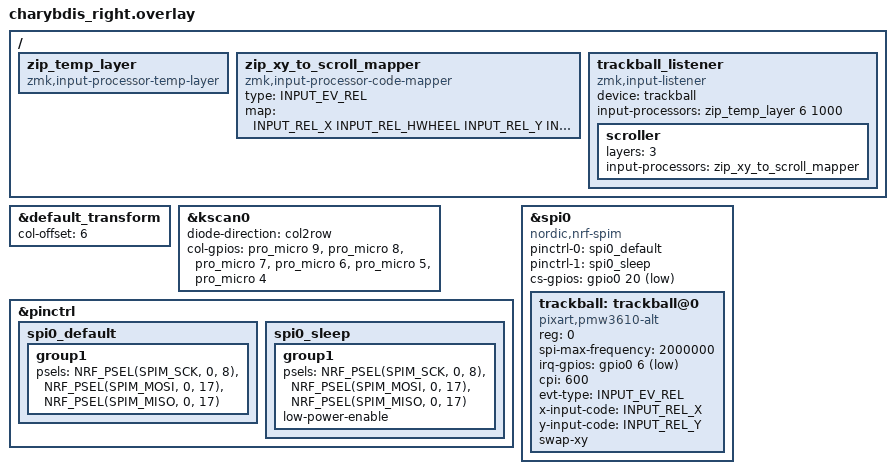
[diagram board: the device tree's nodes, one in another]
/*
 * Copyright (c) 2022 Duccio Breschi
 *
 * SPDX-License-Identifier: MIT
 */
#include <zephyr/dt-bindings/input/input-event-codes.h>
#include "charybdis.dtsi"

&default_transform {
    col-offset = <6>;
};

&kscan0 {
    diode-direction = "col2row";
    col-gpios
        = <&pro_micro 9 (GPIO_ACTIVE_HIGH)> // COL0
        , <&pro_micro 8 (GPIO_ACTIVE_HIGH)> // COL1
        , <&pro_micro 7 (GPIO_ACTIVE_HIGH)> // COL2
        , <&pro_micro 6 (GPIO_ACTIVE_HIGH)> // COL3
        , <&pro_micro 5 (GPIO_ACTIVE_HIGH)> // COL4
        , <&pro_micro 4 (GPIO_ACTIVE_HIGH)> // COL5
    ;
};

&pinctrl {
    spi0_default: spi0_default {
        group1 {
            psels = <NRF_PSEL(SPIM_SCK, 0, 8)>,
                <NRF_PSEL(SPIM_MOSI, 0, 17)>,
                <NRF_PSEL(SPIM_MISO, 0, 17)>;
        };
    };

    spi0_sleep: spi0_sleep {
        group1 {
            psels = <NRF_PSEL(SPIM_SCK, 0, 8)>,
                <NRF_PSEL(SPIM_MOSI, 0, 17)>,
                <NRF_PSEL(SPIM_MISO, 0, 17)>;
            low-power-enable;
        };
    };
};

&spi0 {
    status = "okay";
    compatible = "nordic,nrf-spim";
    pinctrl-0 = <&spi0_default>;
    pinctrl-1 = <&spi0_sleep>;
    pinctrl-names = "default", "sleep";
    cs-gpios = <&gpio0 20 GPIO_ACTIVE_LOW>;

trackball: trackball@0 {
        status = "okay";
        compatible = "pixart,pmw3610-alt";
        reg = <0>;
        spi-max-frequency = <2000000>;
        irq-gpios = <&gpio0 6 (GPIO_ACTIVE_LOW | GPIO_PULL_UP)>;
        cpi = <600>;
        evt-type = <INPUT_EV_REL>;
        x-input-code = <INPUT_REL_X>;
        y-input-code = <INPUT_REL_Y>;
        /* invert-x; */
        swap-xy;
    };
};

/ {
    /omit-if-no-ref/ zip_temp_layer: zip_temp_layer {
        compatible = "zmk,input-processor-temp-layer";
        #input-processor-cells = <2>;
    };

    /omit-if-no-ref/ zip_xy_to_scroll_mapper: zip_xy_to_scroll_mapper {
        compatible = "zmk,input-processor-code-mapper";
        #input-processor-cells = <0>;
        type = <INPUT_EV_REL>;
        map = <INPUT_REL_X INPUT_REL_HWHEEL INPUT_REL_Y INPUT_REL_WHEEL>;
    };

    trackball_listener: trackball_listener {
        compatible = "zmk,input-listener";
        device = <&trackball>;

        /* Temporarily activates Layer 6 (Mouse) on movement for 1000ms */
        input-processors = <&zip_temp_layer 6 1000>;

        /* Converts trackball movement to scroll actions on Layer 3 (Symbol) */
        scroller {
            layers = <3>;
            input-processors = <&zip_xy_to_scroll_mapper>;
        };
    };
};
